# S6E1A1xB register map
Vendor: Cypress; File version: 2.1
CPU: CM0PLUS r0p1, little endian, no MPU, no FPU, 2 interrupt priority bits
Registers are 32-bit, read-write, reset 0x0 unless marked. A register's access mark holds for its fields unless they carry their own. Offsets are from the block's base; [hi:lo] are bit positions; {n}, {i} and the like mark numbered series; 'fields as' and 'values as' point back to an identical list.

## WC — Watch Counter
Base 0x4003A000
0x00 WCRD 8-bit ro — Watch Counter Read Register [BHW]
  [5:0] CTR — Counter read bits
0x01 WCRL 8-bit — Watch Counter Reload Register [BHW]
  [5:0] RLC — Counter reload value setting bits
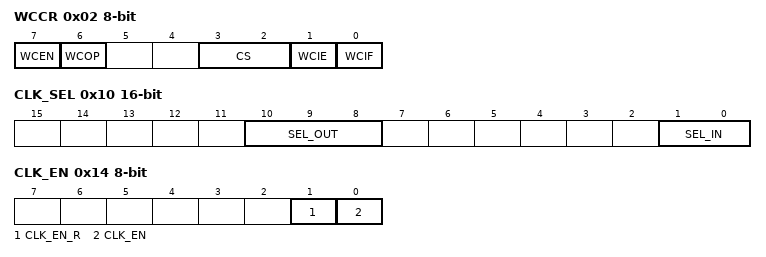
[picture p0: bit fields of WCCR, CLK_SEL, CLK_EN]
0x02 WCCR 8-bit — Watch Counter Control Register [BHW]
  [7] WCEN — Watch counter operation enable bit
  [6] WCOP ro — Watch counter operating state flag
  [3:2] CS — Count clock select bits
  [1] WCIE — Interrupt request enable bit
  [0] WCIF — Interrupt request flag bit
0x10 CLK_SEL 16-bit — Clock Selection Register [BHW]
  [10:8] SEL_OUT — Output clock selection bit
  [1:0] SEL_IN — Input clock selection bit
0x14 CLK_EN 8-bit — Division Clock Enable Register [BHW]
  [1] CLK_EN_R — Division clock enable read bit
  [0] CLK_EN — Division clock enable bit

## LSCRP — Low-speed CR Prescaler Register
Base 0x4003C000
0x00 LCR_PRSLD 8-bit — Low-speed CR Prescaler Control Register [BHW]
  [5:0] LCR_PRSLD — Low-speed CR Prescaler Load

## DMAC — DMAC Registers
Base 0x40060000
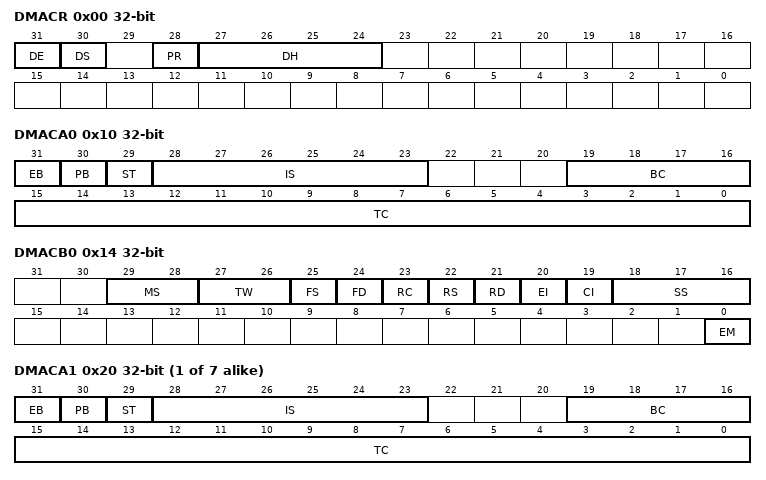
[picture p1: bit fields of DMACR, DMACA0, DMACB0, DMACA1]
0x00 DMACR — Entire DMAC Configuration Register [BHW]
  [31] DE — DMA Enable (all-channel operation enable bit)
  [30] DS — DMA Stop
  [28] PR — Priority Rotation
  [27:24] DH — DMA Halt (All-channel pause bit)
0x10 DMACA0 — Configuration A Register [BHW]
  [31] EB — Enable bit (individual-channel operation enable bit)
  [30] PB — Pause bit (individual-channel pause bit)
  [29] ST — Software Trigger
  [28:23] IS — Input Select
  [19:16] BC — Block Count
  [15:0] TC — Transfer Count
0x14 DMACB0 — Configuration B Register [BHW]
  [29:28] MS — Mode Select
  [27:26] TW — Transfer Width
  [25] FS — Fixed Source
  [24] FD — Fixed Destination
  [23] RC — Reload Count (BC/TC reload)
  [22] RS — Reload Source
  [21] RD — Reload Destination
  [20] EI — Error Interrupt (unsuccessful transfer completion interrupt enable)
  [19] CI — Completion Interrupt (successful transfer completion interrupt enable)
  [18:16] SS — Stop Status (stop status notification)
  [0] EM — Enable bit Mask (EB bit clear mask)
{0x18+0x10*i} DMACSA{i} (i=0..7) — Transfer Source Address Register {i} [BHW]
{0x1C+0x10*i} DMACDA{i} (i=0..7) — Transfer Destination Address Register {i} [BHW]
{0x10+0x10*i} DMACA{i} (i=1..7) — Configuration A Register {i} [BHW]
  fields as DMACA0
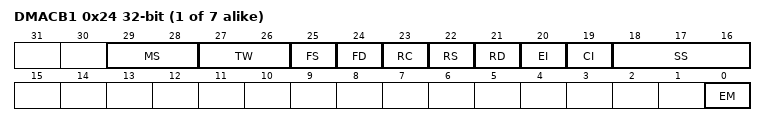
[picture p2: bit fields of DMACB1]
{0x14+0x10*i} DMACB{i} (i=1..7) — Configuration B Register {i} [BHW]
  fields as DMACB0

## MTB_DWT — Micro Trace Buffer Data Watchpoint and Trace Registers
Base 0xF0001000
0x00 CMP_ADDR_START — MTB_DWT Address Compare Start trace Register [BHW]
  [31:0] ADCMP_STA — MTB_DWT address comparison start trace bits
0x04 CMP_DATA_START — MTB_DWT Data Compare Start trace Register [BHW]
  [31:0] DTCMP_STA — MTB_DWT data comparison start trace bits
0x08 CMP_MASK_START — MTB_DWT Mask Data Compare Start Trace Register [BHW]
  [31:0] MSK_STA — MTB_DWT data compare start trace register mask bits
0x10 CMP_ADDR_STOP — MTB_DWT Address Compare Stop trace Register [BHW]
  [31:0] ADCMP_STO — MTB_DWT address comparison stop trace bits
0x14 CMP_DATA_STOP — MTB_DWT Data Compare Stop trace Register [BHW]
  [31:0] DTCMP_STO — MTB_DWT data comparison stop trace bits
0x18 CMP_MASK_STOP — MTB_DWT Mask Data Compare Stop Trace Register [BHW]
  [31:0] MSK_STO — MTB_DWT data compare stop trace register mask bits
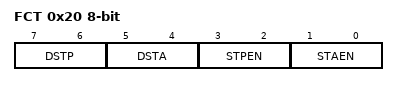
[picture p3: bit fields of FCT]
0x20 FCT 8-bit — MTB_DWT Function Register [BHW]
  [7:6] DSTP — Data size stop bits
  [5:4] DSTA — Data size start bits
  [3:2] STPEN — Enable MTB_DWT stop MTB function bits
  [1:0] STAEN — Enable MTB_DWT start MTB function bits
{0xFC0+4i} PID{i} ro (i=4..7) — Peripheral ID{i} Register [BHW]
  [31:0] PERID — Peripheral ID bits
0xFE0 PID0 ro reset 0x16 — Peripheral ID0 Register [BHW]
  [31:0] PERID — Peripheral ID bits
0xFE4 PID1 ro reset 0x48 — Peripheral ID1 Register [BHW]
  [31:0] PERID — Peripheral ID bits
0xFE8 PID2 ro reset 0x8 — Peripheral ID2 Register [BHW]
  [31:0] PERID — Peripheral ID bits
0xFEC PID3 ro — Peripheral ID3 Register [BHW]
  [31:0] PERID — Peripheral ID bits
0xFF0 CID0 ro reset 0xD — Component ID0 Register [BHW]
  [31:0] CPNTID — Component ID bits
0xFF4 CID1 ro reset 0x90 — Component ID1 Register [BHW]
  [31:0] CPNTID — Component ID bits
0xFF8 CID2 ro reset 0x5 — Component ID2 Register [BHW]
  [31:0] CPNTID — Component ID bits
0xFFC CID3 ro reset 0xB1 — Component ID3 Register [BHW]
  [31:0] CPNTID — Component ID bits

## FASTIO — Fast GPIO Registers
Base 0xF8000000
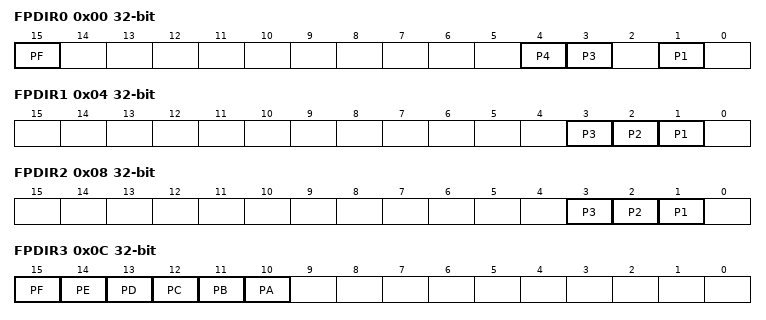
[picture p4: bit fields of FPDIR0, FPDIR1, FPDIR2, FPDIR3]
0x00 FPDIR0 ro — Fast GPIO Input Data Register 0 [BHW]
  [15] PF rw — Bit15 of FPDIR0
  [4] P4 rw — Bit4 of FPDIR0
  [3] P3 rw — Bit3 of FPDIR0
  [1] P1 rw — Bit1 of FPDIR0
0x04 FPDIR1 ro — Fast GPIO Input Data Register 1 [BHW]
  [3] P3 rw — Bit3 of FPDIR1
  [2] P2 rw — Bit2 of FPDIR1
  [1] P1 rw — Bit1 of FPDIR1
0x08 FPDIR2 ro — Fast GPIO Input Data Register 2 [BHW]
  [3] P3 rw — Bit3 of FPDIR2
  [2] P2 rw — Bit2 of FPDIR2
  [1] P1 rw — Bit1 of FPDIR2
0x0C FPDIR3 ro — Fast GPIO Input Data Register 3 [BHW]
  [15] PF rw — Bit15 of FPDIR3
  [14] PE rw — Bit14 of FPDIR3
  [13] PD rw — Bit13 of FPDIR3
  [12] PC rw — Bit12 of FPDIR3
  [11] PB rw — Bit11 of FPDIR3
  [10] PA rw — Bit10 of FPDIR3
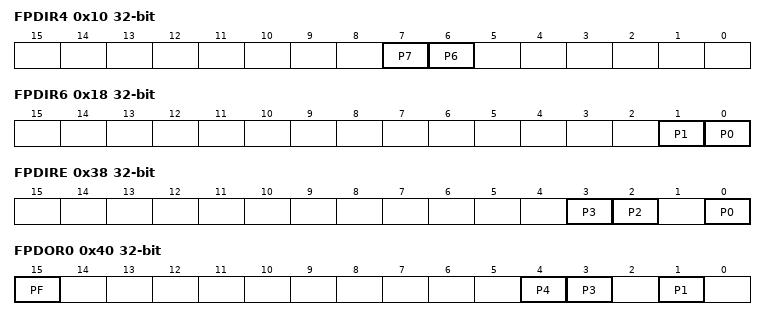
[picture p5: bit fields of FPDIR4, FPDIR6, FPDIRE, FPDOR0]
0x10 FPDIR4 ro — Fast GPIO Input Data Register 4 [BHW]
  [7] P7 rw — Bit7 of FPDIR4
  [6] P6 rw — Bit6 of FPDIR4
0x14 FPDIR5 ro reset not defined — Fast GPIO Input Data Register 5 [BHW]
0x18 FPDIR6 ro — Fast GPIO Input Data Register 6 [BHW]
  [1] P1 rw — Bit1 of FPDIR6
  [0] P0 rw — Bit0 of FPDIR6
{0x0+4i} FPDIR{i} ro reset not defined (i=7..9) — Fast GPIO Input Data Register {i} [BHW]
0x28 FPDIRA ro reset not defined — Fast GPIO Input Data Register A [BHW]
0x2C FPDIRB ro reset not defined — Fast GPIO Input Data Register B [BHW]
0x30 FPDIRC ro reset not defined — Fast GPIO Input Data Register C [BHW]
0x34 FPDIRD ro reset not defined — Fast GPIO Input Data Register D [BHW]
0x38 FPDIRE ro — Fast GPIO Input Data Register E [BHW]
  [3] P3 rw — Bit3 of FPDIRE
  [2] P2 rw — Bit2 of FPDIRE
  [0] P0 rw — Bit0 of FPDIRE
0x3C FPDIRF ro reset not defined — Fast GPIO Input Data Register F [BHW]
0x40 FPDOR0 — Fast GPIO Output Data Register 0 [BHW]
  [15] PF — Bit15 of FPDOR0
  [4] P4 — Bit4 of FPDOR0
  [3] P3 — Bit3 of FPDOR0
  [1] P1 — Bit1 of FPDOR0
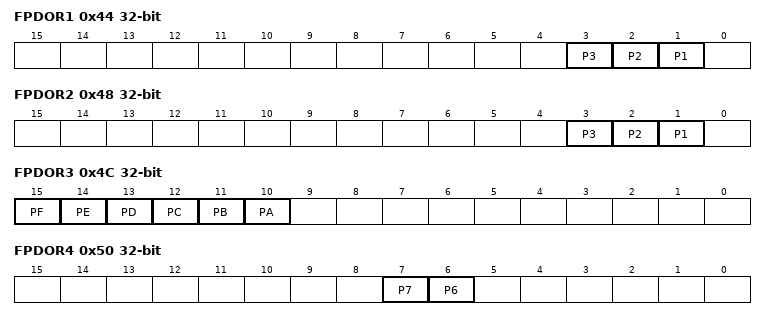
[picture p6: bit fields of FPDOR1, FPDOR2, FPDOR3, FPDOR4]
0x44 FPDOR1 — Fast GPIO Output Data Register 1 [BHW]
  [3] P3 — Bit3 of FPDOR1
  [2] P2 — Bit2 of FPDOR1
  [1] P1 — Bit1 of FPDOR1
0x48 FPDOR2 — Fast GPIO Output Data Register 2 [BHW]
  [3] P3 — Bit3 of FPDOR2
  [2] P2 — Bit2 of FPDOR2
  [1] P1 — Bit1 of FPDOR2
0x4C FPDOR3 — Fast GPIO Output Data Register 3 [BHW]
  [15] PF — Bit15 of FPDOR3
  [14] PE — Bit14 of FPDOR3
  [13] PD — Bit13 of FPDOR3
  [12] PC — Bit12 of FPDOR3
  [11] PB — Bit11 of FPDOR3
  [10] PA — Bit10 of FPDOR3
0x50 FPDOR4 — Fast GPIO Output Data Register 4 [BHW]
  [7] P7 — Bit7 of FPDOR4
  [6] P6 — Bit6 of FPDOR4
0x54 FPDOR5 reset not defined — Fast GPIO Output Data Register 5 [BHW]
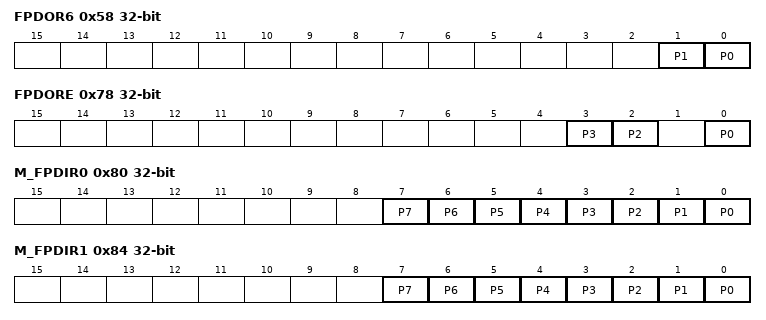
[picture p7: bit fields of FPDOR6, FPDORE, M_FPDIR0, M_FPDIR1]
0x58 FPDOR6 — Fast GPIO Output Data Register 6 [BHW]
  [1] P1 — Bit1 of FPDOR6
  [0] P0 — Bit0 of FPDOR6
{0x40+4i} FPDOR{i} reset not defined (i=7..9) — Fast GPIO Output Data Register {i} [BHW]
0x68 FPDORA reset not defined — Fast GPIO Output Data Register A [BHW]
0x6C FPDORB reset not defined — Fast GPIO Output Data Register B [BHW]
0x70 FPDORC reset not defined — Fast GPIO Output Data Register C [BHW]
0x74 FPDORD reset not defined — Fast GPIO Output Data Register D [BHW]
0x78 FPDORE — Fast GPIO Output Data Register E [BHW]
  [3] P3 — Bit3 of FPDORE
  [2] P2 — Bit2 of FPDORE
  [0] P0 — Bit0 of FPDORE
0x7C FPDORF reset not defined — Fast GPIO Output Data Register F [BHW]
0x80 M_FPDIR0 ro — Mirror Fast GPIO Input Data Register 0 [BHW]
  [n] P{n} rw (n=0..7) — Bit{n} of M_FPDIR0
0x84 M_FPDIR1 ro — Mirror Fast GPIO Input Data Register 1 [BHW]
  [n] P{n} rw (n=0..7) — Bit{n} of M_FPDIR1
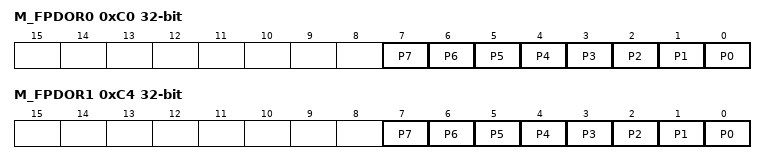
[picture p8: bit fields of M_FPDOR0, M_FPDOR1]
0xC0 M_FPDOR0 — Mirror Fast GPIO Output Data Register 0 [BHW]
  [n] P{n} (n=0..7) — Bit{n} of M_FPDOR0
0xC4 M_FPDOR1 — Mirror Fast GPIO Output Data Register 1 [BHW]
  [n] P{n} (n=0..7) — Bit{n} of M_FPDOR1
